VERSION ""

NS_ :

BS_:

BU_: ECU1 ECU2

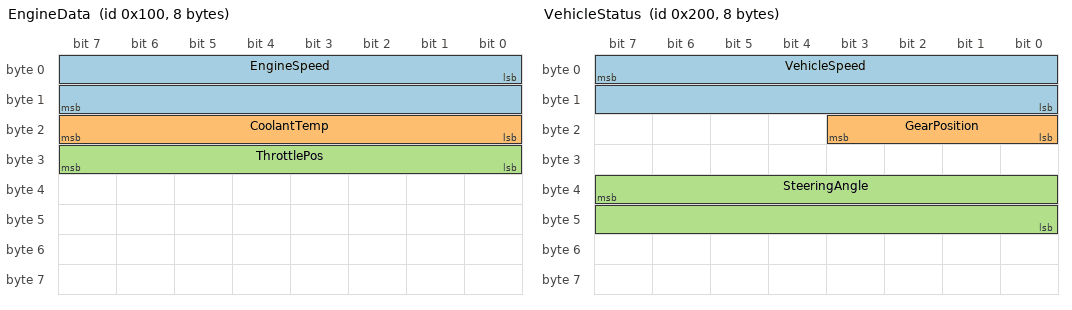
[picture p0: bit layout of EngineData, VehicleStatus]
BO_ 256 EngineData: 8 ECU1
 SG_ EngineSpeed : 0|16@1+ (0.25,0) [0|16383.75] "rpm" ECU2
 SG_ CoolantTemp : 16|8@1+ (1,-40) [-40|215] "degC" ECU2
 SG_ ThrottlePos : 24|8@1+ (0.4,0) [0|102] "%" ECU2

BO_ 512 VehicleStatus: 8 ECU2
 SG_ VehicleSpeed : 7|16@0+ (0.01,0) [0|655.35] "km/h" ECU1
 SG_ GearPosition : 16|4@1+ (1,0) [0|15] "" ECU1
 SG_ SteeringAngle : 39|16@0- (0.1,0) [-3276.8|3276.7] "deg" ECU1

VAL_ 512 GearPosition 0 "P" 1 "R" 2 "N" 3 "D" ;
